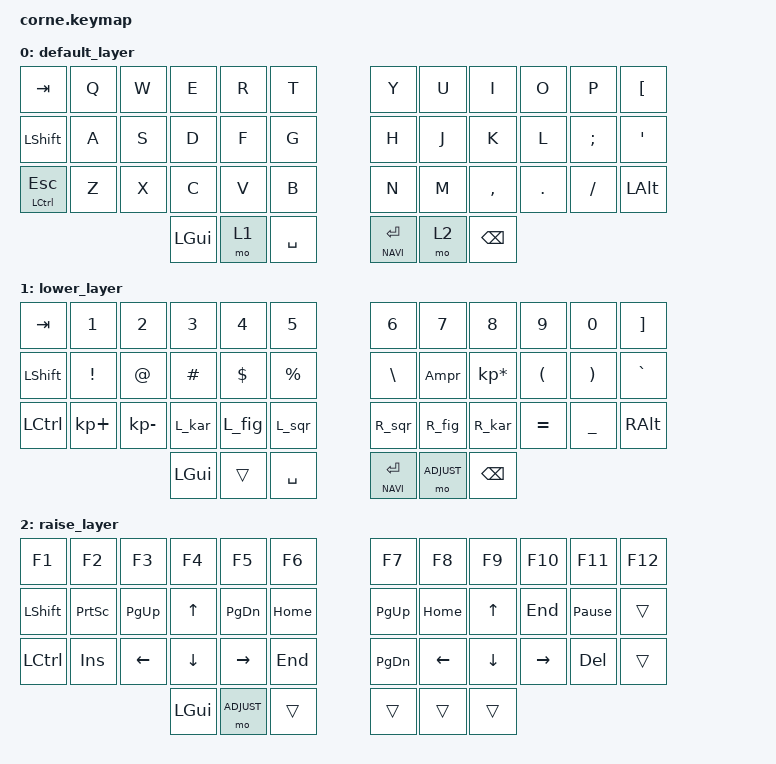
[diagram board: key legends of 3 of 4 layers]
/*
 * Copyright (c) 2020 The ZMK Contributors
 *
 * SPDX-License-Identifier: MIT
 * To use home rows - &hm LSHFT F
 */

#include <behaviors.dtsi>
#include <dt-bindings/zmk/bt.h>
#include <dt-bindings/zmk/keys.h>
#include <dt-bindings/zmk/mouse.h>

#define QWERTY 0
#define NUMB 1
#define NAVI 2
#define ADJUST 3

/ {
    behaviors {
        hm: homerow_mods {
            compatible = "zmk,behavior-hold-tap";
            label = "HOMEROW_MODS";
            #binding-cells = <2>;
            tapping-term-ms = <150>;
            quick_tap_ms = <0>;
            flavor = "tap-preferred";
            bindings = <&kp>, <&kp>;
        };
    };

    macros {
        Ampr: Symboll_ampersant {
            compatible = "zmk,behavior-macro";
            #binding-cells = <0>;
            bindings =
                <&macro_press>,
                <&kp LALT>,
                <&macro_tap>,
                <&kp KP_NUMBER_3 &kp KP_NUMBER_8>,
                <&macro_release>,
                <&kp LALT>;

            label = "SYMBOLL_AMPERSANT";
        };

        R_sqr: R_sqr {
            compatible = "zmk,behavior-macro";
            #binding-cells = <0>;
            bindings =
                <&macro_press>,
                <&kp LALT>,
                <&macro_tap>,
                <&kp KP_NUMBER_9 &kp KP_NUMBER_3>,
                <&macro_release>,
                <&kp LALT>;

            label = "R_SQR";
        };

        L_sqr: L_sqr {
            compatible = "zmk,behavior-macro";
            #binding-cells = <0>;
            bindings =
                <&macro_press>,
                <&kp LALT>,
                <&macro_tap>,
                <&kp KP_NUMBER_9 &kp KP_NUMBER_1>,
                <&macro_release>,
                <&kp LALT>;

            label = "L_SQR";
        };

        L_fig: L_fig {
            compatible = "zmk,behavior-macro";
            #binding-cells = <0>;
            bindings =
                <&macro_press>,
                <&kp LALT>,
                <&macro_tap>,
                <&kp KP_NUMBER_1 &kp KP_NUMBER_2 &kp KP_NUMBER_3>,
                <&macro_release>,
                <&kp LALT>;

            label = "L_FIG";
        };

        R_fig: R_fig {
            compatible = "zmk,behavior-macro";
            #binding-cells = <0>;
            bindings =
                <&macro_press>,
                <&kp LALT>,
                <&macro_tap>,
                <&kp KP_NUMBER_1 &kp KP_NUMBER_2 &kp KP_NUMBER_5>,
                <&macro_release>,
                <&kp LALT>;

            label = "R_FIG";
        };

        L_kar: L_kar {
            compatible = "zmk,behavior-macro";
            #binding-cells = <0>;
            bindings =
                <&macro_press>,
                <&kp LALT>,
                <&macro_tap>,
                <&kp KP_NUMBER_6 &kp KP_NUMBER_0>,
                <&macro_release>,
                <&kp LALT>;

            label = "L_KAR";
        };

        R_kar: R_kar {
            compatible = "zmk,behavior-macro";
            #binding-cells = <0>;
            bindings =
                <&macro_press>,
                <&kp LALT>,
                <&macro_tap>,
                <&kp KP_NUMBER_6 &kp KP_NUMBER_2>,
                <&macro_release>,
                <&kp LALT>;

            label = "R_KAR";
        };
    };

    keymap {
        compatible = "zmk,keymap";

        default_layer {
            // .--------------------------------------------------------------.       .-----------------------------------------------------------.
            // |   Tab        |    Q    |    W   |   E    |    R    |    T    |       |   Y   |    U    |    I    |    O    |     P    |    [     |
            // |--------------+---------+--------+--------+---------+---------|       |-------+---------+---------+---------+----------+----------|
            // |   SHFT       |    A    |    S   |   D    |    F    |    G    |       |   H   |    J    |    K    |    L    |     ;    |     '    |
            // |--------------+---------+--------+--------+---------+---------|       |-------+---------+---------+---------+----------+----------|
            // |   CTRL/ESC   |    Z    |    X   |   C    |    V    |    B    |       |   N   |    M    |    ,    |    .    |     /    |    ALT   |
            // '---------------------------------+--------+---------+---------+       |-------+---------+---------+-------------------------------'
            //                                   |  GUI   |   MO1   |   SPC   |       |  ENTR |   MO2   |  BSPC   |
            //                                   '--------+---------+---------'       '-------+---------+---------'

            bindings = <
&kp TAB        &kp Q  &kp W  &kp E     &kp R  &kp T        &kp Y         &kp U  &kp I      &kp O    &kp P     &kp LBKT
&kp LSHFT      &kp A  &kp S  &kp D     &kp F  &kp G        &kp H         &kp J  &kp K      &kp L    &kp SEMI  &kp SQT
&mt LCTRL ESC  &kp Z  &kp X  &kp C     &kp V  &kp B        &kp N         &kp M  &kp COMMA  &kp DOT  &kp FSLH  &kp LALT
                             &kp LGUI  &mo 1  &kp SPACE    &lt NAVI RET  &mo 2  &kp BSPC
            >;
        };

        lower_layer {
            // .--------------------------------------------------------------.       .-----------------------------------------------------------.
            // |   ESC        |    1    |    2   |   3    |    4    |    5    |       |   6   |    7    |    8    |    9    |     0    |    `     |
            // |--------------+---------+--------+--------+---------+---------|       |-------+---------+---------+---------+----------+----------|
            // |   SHFT       |    !    |    @   |   #    |    $    |    %    |       |   ^   |    &    |    *    |    (    |     )    |     :    |
            // |--------------+---------+--------+--------+---------+---------|       |-------+---------+---------+---------+----------+----------|
            // |   CTRL       |    +    |   -    |   <    |    {    |    [    |       |   ]   |    }    |    >    |    =    |     _    |   ALT    |
            // '---------------------------------+--------+---------+---------+       |-------+---------+---------+-------------------------------'
            //                                   |  GUI   |         |   SPC   |       |  ENTR |    MO3  |  BSPC   |
            //                                   '--------+---------+---------'       '-------+---------+---------'

            bindings = <
&kp TAB    &kp N1       &kp N2        &kp N3    &kp N4    &kp N5       &kp N6         &kp N7      &kp N8           &kp N9     &kp N0          &kp RIGHT_BRACKET
&kp LSHFT  &kp EXCL     &kp AT        &kp HASH  &kp DLLR  &kp PRCNT    &kp BACKSLASH  &Ampr       &kp KP_MULTIPLY  &kp LPAR   &kp RPAR        &kp GRAVE
&kp LCTRL  &kp KP_PLUS  &kp KP_MINUS  &L_kar    &L_fig    &L_sqr       &R_sqr         &R_fig      &R_kar           &kp EQUAL  &kp UNDERSCORE  &kp RALT
                                      &kp LGUI  &trans    &kp SPACE    &lt NAVI RET   &mo ADJUST  &kp BSPC
            >;
        };

        raise_layer {
            // .---------------------------------------------------------.       .----------------------------------------------------------------.
            // |   F1    |   F2  |   F3   |   F4   |    F5    |    F6    |       |    F7    |    F8    |    F9    |   F10   |   F11    |   F12    |
            // |---------+-------+--------+--------+----------+----------|       |----------+----------+----------+---------+----------+----------|
            // |  SHFT   | PSCRN |   PU   |   UP   |    PD    |   HOME   |       |   HOME   |    PU    |    UP    |   PD    |   BREAK  |          |
            // |---------+-------+--------+--------+----------+----------|       |----------+----------+----------+---------+----------+----------|
            // |  CTRL   |       |  LEFT  |  DOWN  |   RIGHT  |   END    |       |   END    |   LEFT   |   DOWN   |  RIGHT  |   DEL    |          |
            // '--------------------------+--------+----------+----------+       |----------+----------+----------+-------------------------------'
            //                            |  GUI   |   MO3    |          |       |          |          |          |
            //                            '--------+----------+----------'       '----------+----------+----------'

            bindings = <
&kp F1      &kp F2      &kp F3          &kp F4          &kp F5           &kp F6      &kp F7         &kp F8          &kp F9          &kp F10          &kp F11          &kp F12
&kp LSHIFT  &kp PSCRN   &kp PAGE_UP     &kp UP_ARROW    &kp PAGE_DOWN    &kp HOME    &kp PG_UP      &kp HOME        &kp UP_ARROW    &kp END          &kp PAUSE_BREAK  &trans
&kp LCTRL   &kp INSERT  &kp LEFT_ARROW  &kp DOWN_ARROW  &kp RIGHT_ARROW  &kp END     &kp PAGE_DOWN  &kp LEFT_ARROW  &kp DOWN_ARROW  &kp RIGHT_ARROW  &kp DEL          &trans
                                        &kp LGUI        &mo ADJUST       &trans      &trans         &trans          &trans
            >;
        };

        adjust_layer {
            // .--------------------------------------------------------.       .----------------------------------------------------------------.
            // |  BTCLR  |   BT1  |  BT2   |  BT3   |   BT4   |   BT5   |       |        |          |         |         |          |             |
            // |---------+--------+--------+--------+---------+---------|       |--------+----------+---------+---------+----------+-------------|
            // |         |        |  MB4   |  RCLK  |   MB5   | BRI_UP  |       |        |Play/Pause|   VOL+  |         |          |             |
            // |---------+--------+--------+--------+---------+---------|       |--------+----------+---------+---------+----------+-------------|
            // |         |        |        |        |         | BRI DN  |       |        |   Prev   |   VOL-  |   Next  |          |             |
            // '---------------------------+--------+---------+---------+       |--------+----------+---------+----------------------------------'
            //                             |        |         |         |       |        |          |         |
            //                             '--------+---------+---------'       '--------+----------+---------'

            bindings = <
&bt BT_CLR  &bt BT_SEL 0  &bt BT_SEL 1  &bt BT_SEL 2  &bt BT_SEL 3  &bt BT_SEL 4    &none   &none             &none              &none           &none  &none
&none       &none         &mkp MB4      &kp K_CMENU   &mkp MB5      &kp C_BRI_UP    &none   &kp C_PLAY_PAUSE  &kp C_VOLUME_UP    &none           &none  &none
&none       &none         &none         &none         &none         &kp C_BRI_DN    &none   &kp C_PREVIOUS    &kp C_VOLUME_DOWN  &kp LA(C_NEXT)  &none  &none
                                        &trans        &trans        &trans          &trans  &trans
            >;
        };
    };
};
